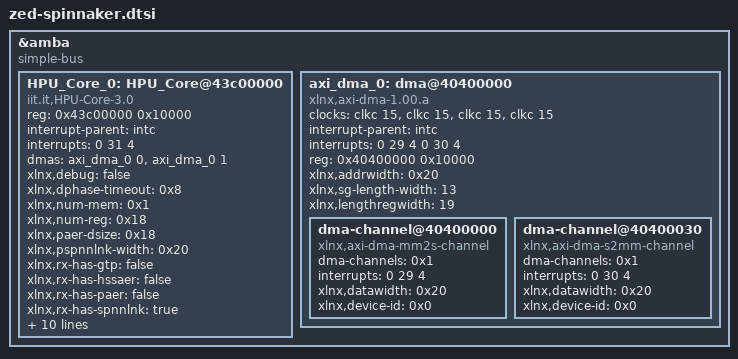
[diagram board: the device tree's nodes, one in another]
&amba {
	#address-cells = <1>;
	#size-cells = <1>;
	compatible = "simple-bus";
	ranges ;
	HPU_Core_0: HPU_Core@43c00000 {
		compatible = "iit.it,HPU-Core-3.0";
		reg = <0x43c00000 0x10000>;
		interrupt-parent = <&intc>;
		interrupts = <0 31 4>;

		dmas = <&axi_dma_0 0>,<&axi_dma_0 1>;
		dma-names = "tx", "rx";

		xlnx,debug = "false";
		xlnx,dphase-timeout = <0x8>;
		xlnx,num-mem = <0x1>;
		xlnx,num-reg = <0x18>;
		xlnx,paer-dsize = <0x18>;
		xlnx,pspnnlnk-width = <0x20>;
		xlnx,rx-has-gtp = "false";
		xlnx,rx-has-hssaer = "false";
		xlnx,rx-has-paer = "false";
		xlnx,rx-has-spnnlnk = "true";
		xlnx,rx-hssaer-n-chan = <0x3>;
		xlnx,s-axi-min-size = <0x000001FF>;
		xlnx,slv-awidth = <0x20>;
		xlnx,slv-dwidth = <0x20>;
		xlnx,tx-has-gtp = "false";
		xlnx,tx-has-hssaer = "false";
		xlnx,tx-has-paer = "false";
		xlnx,tx-has-spnnlnk = "true";
		xlnx,tx-hssaer-n-chan = <0x2>;
		xlnx,use-wstrb = <0x1>;
	};

	axi_dma_0: dma@40400000 {
		#dma-cells = <1>;
		clock-names = "s_axi_lite_aclk", "m_axi_sg_aclk", "m_axi_mm2s_aclk", "m_axi_s2mm_aclk";
		clocks = <&clkc 15>, <&clkc 15>, <&clkc 15>, <&clkc 15>;
		compatible = "xlnx,axi-dma-1.00.a";
		interrupt-names = "mm2s_introut", "s2mm_introut";
		interrupt-parent = <&intc>;
		interrupts = <0 29 4 0 30 4>;
		reg = <0x40400000 0x10000>;
		xlnx,addrwidth = <0x20>;
		xlnx,sg-length-width = <13>;
		xlnx,lengthregwidth = <19>;
		dma-channel@40400000 {
			compatible = "xlnx,axi-dma-mm2s-channel";
			dma-channels = <0x1>;
			interrupts = <0 29 4>;
			xlnx,datawidth = <0x20>;
			xlnx,device-id = <0x0>;
		};
		dma-channel@40400030 {
			compatible = "xlnx,axi-dma-s2mm-channel";
			dma-channels = <0x1>;
			interrupts = <0 30 4>;
			xlnx,datawidth = <0x20>;
			xlnx,device-id = <0x0>;
		};
	};
};
